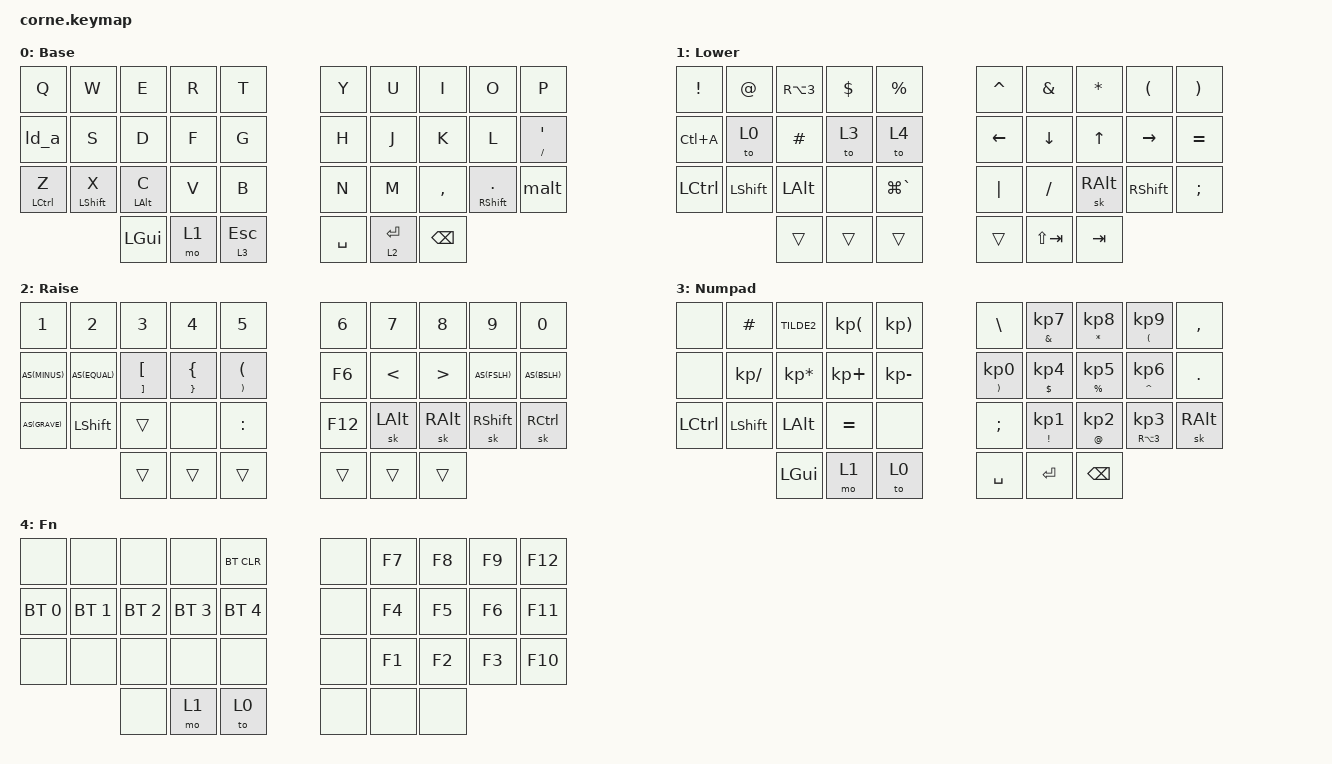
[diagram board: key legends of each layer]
/*
 * Copyright (c) 2020 The ZMK Contributors
 *
 * SPDX-License-Identifier: MIT
 */

#include <behaviors.dtsi>
#include <dt-bindings/zmk/keys.h>
#include <dt-bindings/zmk/bt.h>


#define AS(keycode) &as LS(keycode) keycode

/ {
    chosen {
        zmk,physical-layout = &foostan_corne_5col_layout;
    };

    combos {
        compatible = "zmk,combos";

        // key positions        
        // ------------------------------------------------------------
        // | 0  | 1  | 2  | 3  | 4  |        | 5  | 6  | 7  | 8  | 9  |
        // | 10 | 11 | 12 | 13 | 14 |        | 15 | 16 | 17 | 18 | 19 | 
        // | 20 | 21 | 22 | 23 | 24 |        | 25 | 26 | 27 | 28 | 29 |
        //           | 30 | 31 | 32 |        | 33 | 34 | 35 |

        // combo_ralt {
        //     bindings = <&kp RIGHT_ALT>;
        //     key-positions = <28 35>;
        // };  

        // combo_lalt {
        //     bindings = <&kp LEFT_ALT>;
        //     key-positions = <21 30>;
        // };
    };

    behaviors {
        as: auto_shift {
            compatible = "zmk,behavior-hold-tap";
            #binding-cells = <2>;
            tapping_term_ms = <200>;
            quick_tap_ms = <0>;
            flavor = "tap-preferred";
            bindings = <&kp>, <&kp>;
        };

        ld_a: leader {
            compatible = "zmk,behavior-mod-morph";
            #binding-cells = <0>;
            bindings = <&kp A>, <&kp LC(A)>;
            mods = <(MOD_LGUI|MOD_RGUI)>;
        };

        malt: morph_alt {
            compatible = "zmk,behavior-mod-morph";
            #binding-cells = <0>;
            bindings = <&mt RCTRL SEMI>, <&sk RALT>;
            mods = <(MOD_RSFT)>;
        };
    };

    keymap {
        compatible = "zmk,keymap";

        default_layer {
            display-name = "Base";

            // -----------------------------------------------------------------------------------------
            // |  Q    |  W    |  E    | R   | T   |     | Y   | U   | I    | O    | P        |
            // |  A    |  S    |  D    | F   | G   |     | H   | J   | K    | L    | /'       | 
            // |  Z LC |  X LS |  C LA | V   | B   |     | N   | M   | ,    | . RS | ; RC[LA] |
            //                 | GUI | LWR | ESC |     | SPC | RET | BSPC |

            bindings = <
                &kp Q         &kp W          &kp E       &kp R    &kp T          &kp Y        &kp U       &kp I        &kp O             &kp P
                &ld_a         &kp S          &kp D       &kp F    &kp G          &kp H        &kp J       &kp K        &kp L             &mt FSLH SQT
                &mt LCTRL Z   &mt LSHFT X    &mt LALT C  &kp V    &kp B          &kp N        &kp M       &kp COMMA    &mt RSHFT DOT     &malt
                                             &kp LGUI    &mo 1    &lt 3 ESC      &kp SPACE    &lt 2 RET   &kp BSPC 
            >;
        };

        lower_layer {
            display-name = "Lower";

            // -----------------------------------------------------------------------------------------
            // | !    | @  | £   | $   | %   |          | ^   | &      | *   | (   | )  |
            // | LC+A | L0 | #   | L3  | L4  |          | LFT | DWN    | UP  | RGT | =  |
            // | LC   | LS | LA  |     | LG+`|          | |   | /      |     | RS  | ;  |
            //             | GUI |     | ESC |          | SPC | LS+TAB | TAB |

            bindings = <
                &kp EXCL      &kp AT       &kp RA(N3)   &kp DLLR     &kp PRCNT           &kp CARET   &kp AMPS      &kp ASTRK  &kp LPAR   &kp RPAR
                &kp LC(A)     &to 0        &kp HASH     &to 3        &to 4               &kp LEFT    &kp DOWN      &kp UP     &kp RIGHT  &kp EQUAL 
                &kp LCTRL     &kp LSHFT    &kp LALT     &none        &kp LG(GRAVE)       &kp PIPE    &kp FSLH      &sk RALT   &kp RSHFT  &kp SEMI 
                                           &trans       &trans       &trans              &trans      &kp LS(TAB)   &kp TAB
            >;
        };

        raise_layer {
            display-name = "Raise";

            // -----------------------------------------------------------------------------------------
            // | 1  | 2  | 3   | 4   | 5   |     | 6   | 7   | 8   | 9   | 0   |
            // | -_ | =+ | [   | {   | (   |     | F6  | <   | >   | /?  | \|  |
            // | `~ |    |     |     | :   |     | F12 | LA* | RA* | RS* | RC* |
            //           | GUI |     | SPC |     | SPC |     |     |

            bindings = <
                &kp N1    &kp N2     &kp N3          &kp N4           &kp N5                 &kp N6    &kp N7    &kp N8    &kp N9     &kp N0
                AS(MINUS) AS(EQUAL)  &mt RBKT LBKT   &mt RBRC LBRC    &mt RPAR LPAR          &kp F6    &kp LT    &kp GT    AS(FSLH)   AS(BSLH)
                AS(GRAVE) &kp LSHFT  &trans          &none            &kp COLON              &kp F12   &sk LALT  &sk RALT  &sk RSHFT  &sk RCTRL
                                     &trans          &trans           &trans                 &trans    &trans    &trans
            >;
        };

        extra_1 {
            display-name = "Numpad";

            // -----------------------------------------------------------------------------------------
            // |    | #  | ~   |  (  | )  |         | \  | &7 | *8 | (9 | , |
            // |    | /  | *   |  +  | -  |         | )0 | $4 | %5 | ^6 | . |
            // | LC | LS | LA  |  =  |    |         | ;  | !1 | @2 | #3 | / |
            //           | GUI | LWR | L0 |         | SPC | RET | BSPC |

            bindings = <
                &none     &kp HASH       &kp TILDE2       &kp KP_LPAR   &kp KP_RPAR       &kp BSLH         &mt AMPS KP_N7   &mt ASTRK KP_N8   &mt LPAR KP_N9    &kp COMMA
                &none     &kp KP_DIVIDE  &kp KP_MULTIPLY  &kp KP_PLUS   &kp KP_MINUS      &mt RPAR KP_N0   &mt DLLR KP_N4   &mt PRCNT KP_N5   &mt CARET KP_N6   &kp DOT
                &kp LCTRL &kp LSHFT      &kp LALT         &kp EQL       &none             &kp SEMI         &mt EXCL KP_N1   &mt AT KP_N2      &mt RA(N3) KP_N3  &sk RALT
                                         &kp LGUI         &mo 1         &to 0             &kp SPACE        &kp RET     &kp BSPC 
            >;
        };

        extra_2 {
            display-name = "Fn";
           
            // ----------------------------------------------------------------------
            // |     |     |     |     | BTCLR |         |     | F7 | F8 | F9 | F12 |
            // | BT0 | BT1 | BT2 | BT3 | BT4   |         |     | F4 | F5 | F6 | F11 |
            // |     |     |     |     |       |         |     | F1 | F2 | F3 | F10 |
            //             |     | LWR | L0    |         |     |    |    |
            
            bindings = <
                &none          &none          &none          &none          &bt BT_CLR         &none    &kp F7    &kp F8    &kp F9   &kp F12
                &bt BT_SEL 0   &bt BT_SEL 1   &bt BT_SEL 2   &bt BT_SEL 3   &bt BT_SEL 4       &none    &kp F4    &kp F5    &kp F6   &kp F11
                &none          &none          &none          &none          &none              &none    &kp F1    &kp F2    &kp F3   &kp F10
                                              &none          &mo 1          &to 0              &none    &none     &none 
            >;
        };

        extra_3 {
            status = "reserved";
        };
    };
};
